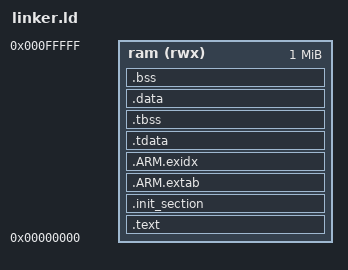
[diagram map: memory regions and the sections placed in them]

MEMORY
{
  ram (rwx) : ORIGIN = 0x00000000, LENGTH = 1M
}

OUTPUT_ARCH(arm)
EXTERN(_vectors)
ENTRY(_stext)
SECTIONS
{
    .text : {
        _stext = ABSOLUTE(.);
        *(.vectors)
        *(.text .text.*)
        *(.fixup)
        *(.gnu.warning)
        *(.rodata .rodata.*)
        *(.gnu.linkonce.t.*)
        *(.glue_7)
        *(.glue_7t)
        *(.got)
        *(.gcc_except_table)
        *(.gnu.linkonce.r.*)
        _etext = ABSOLUTE(.);
    } > ram

    .init_section : {
        _sinit = ABSOLUTE(.);
        KEEP(*(SORT_BY_INIT_PRIORITY(.init_array.*) SORT_BY_INIT_PRIORITY(.ctors.*)))
        KEEP(*(.init_array EXCLUDE_FILE(*crtbegin.o *crtbegin?.o *crtend.o *crtend?.o) .ctors))
        _einit = ABSOLUTE(.);
    } > ram

    .ARM.extab : {
        *(.ARM.extab*)
    } > ram

    __exidx_start = ABSOLUTE(.);
    .ARM.exidx : {
        *(.ARM.exidx*)
    } > ram
    __exidx_end = ABSOLUTE(.);

    .tdata : {
        _stdata = ABSOLUTE(.);
        *(.tdata .tdata.* .gnu.linkonce.td.*);
        _etdata = ABSOLUTE(.);
    } > ram

    .tbss : {
        _stbss = ABSOLUTE(.);
        *(.tbss .tbss.* .gnu.linkonce.tb.* .tcommon);
        _etbss = ABSOLUTE(.);
    } > ram

    _eronly = ABSOLUTE(.);

    .data : {
        _sdata = ABSOLUTE(.);
        *(.data .data.*)
        *(.gnu.linkonce.d.*)
        CONSTRUCTORS
        . = ALIGN(4);
        _edata = ABSOLUTE(.);
    } > ram AT > ram

    .bss : {
        _sbss = ABSOLUTE(.);
        *(.bss .bss.*)
        *(.gnu.linkonce.b.*)
        *(COMMON)
        . = ALIGN(4);
        _ebss = ABSOLUTE(.);
    } > ram

    _module_end = ABSOLUTE(.);

    /* Stabs debugging sections. */

    .stab 0 : { *(.stab) }
    .stabstr 0 : { *(.stabstr) }
    .stab.excl 0 : { *(.stab.excl) }
    .stab.exclstr 0 : { *(.stab.exclstr) }
    .stab.index 0 : { *(.stab.index) }
    .stab.indexstr 0 : { *(.stab.indexstr) }
    .comment 0 : { *(.comment) }
    .debug_abbrev 0 : { *(.debug_abbrev) }
    .debug_info 0 : { *(.debug_info) }
    .debug_line 0 : { *(.debug_line) }
    .debug_pubnames 0 : { *(.debug_pubnames) }
    .debug_aranges 0 : { *(.debug_aranges) }
}
